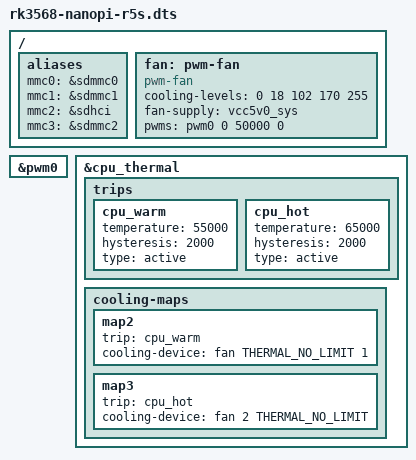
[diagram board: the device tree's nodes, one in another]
/dts-v1/;

#include <rockchip/rk3568-nanopi-r5s.dts>
#include "rk3568-ip.dtsi"
#include "rk3568-ip-rk809.dtsi"

/ {
	aliases {
		mmc0 = &sdmmc0;
		mmc1 = &sdmmc1;
		mmc2 = &sdhci;
		mmc3 = &sdmmc2;
	};
	fan: pwm-fan {
		compatible = "pwm-fan";
		cooling-levels = <0 18 102 170 255>;
		#cooling-cells = <2>;
		fan-supply = <&vcc5v0_sys>;
		pwms = <&pwm0 0 50000 0>;
	};
};

&pwm0 {
	status = "okay";
};

&cpu_thermal {
	trips {
		cpu_warm: cpu_warm {
			temperature = <55000>;
			hysteresis = <2000>;
			type = "active";
		};

		cpu_hot: cpu_hot {
			temperature = <65000>;
			hysteresis = <2000>;
			type = "active";
		};
	};

	cooling-maps {
		map2 {
			trip = <&cpu_warm>;
			cooling-device = <&fan THERMAL_NO_LIMIT 1>;
		};

		map3 {
			trip = <&cpu_hot>;
			cooling-device = <&fan 2 THERMAL_NO_LIMIT>;
		};
	};
};
